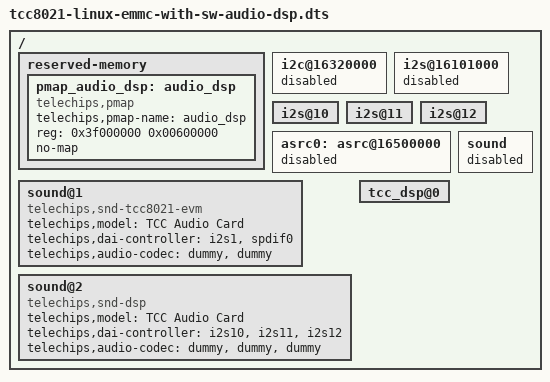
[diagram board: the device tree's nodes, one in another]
/*
 * Device tree for Telechips TCC8020 AVN board
 *
 * Copyright (C) 2016 Telechips Inc. - http://www.telechips.com
 *
 * This file is dual-licensed: you can use it either under the terms
 * of the GPL or the X11 license, at your option. Note that this dual
 * licensing only applies to this file, and not this project as a
 * whole.
 *
 *  a) This file is free software; you can redistribute it and/or
 *     modify it under the terms of the GNU General Public License as
 *     published by the Free Software Foundation; either version 2 of the
 *     License, or (at your option) any later version.
 *
 *     This file is distributed in the hope that it will be useful,
 *     but WITHOUT ANY WARRANTY; without even the implied warranty of
 *     MERCHANTABILITY or FITNESS FOR A PARTICULAR PURPOSE.  See the
 *     GNU General Public License for more details.
 *
 * Or, alternatively,
 *
 *  b) Permission is hereby granted, free of charge, to any person
 *     obtaining a copy of this software and associated documentation
 *     files (the "Software"), to deal in the Software without
 *     restriction, including without limitation the rights to use,
 *     copy, modify, merge, publish, distribute, sublicense, and/or
 *     sell copies of the Software, and to permit persons to whom the
 *     Software is furnished to do so, subject to the following
 *     conditions:
 *
 *     The above copyright notice and this permission notice shall be
 *     included in all copies or substantial portions of the Software.
 *
 *     THE SOFTWARE IS PROVIDED "AS IS", WITHOUT WARRANTY OF ANY KIND,
 *     EXPRESS OR IMPLIED, INCLUDING BUT NOT LIMITED TO THE WARRANTIES
 *     OF MERCHANTABILITY, FITNESS FOR A PARTICULAR PURPOSE AND
 *     NONINFRINGEMENT. IN NO EVENT SHALL THE AUTHORS OR COPYRIGHT
 *     HOLDERS BE LIABLE FOR ANY CLAIM, DAMAGES OR OTHER LIABILITY,
 *     WHETHER IN AN ACTION OF CONTRACT, TORT OR OTHERWISE, ARISING
 *     FROM, OUT OF OR IN CONNECTION WITH THE SOFTWARE OR THE USE OR
 *     OTHER DEALINGS IN THE SOFTWARE.
 */

#include "tcc8021-linux-emmc-fld0800-micom.dts"

/ {
	reserved-memory {
		pmap_audio_dsp: audio_dsp{
			compatible = "telechips,pmap";
			telechips,pmap-name = "audio_dsp";
			reg = <0x3f000000 0x00600000>;
			no-map;
		};
	};

	i2c@16320000 {
		status = "disabled";
	};

	i2s@16101000 {
		status = "disabled";
	};

	i2s@10 {
		status = "okay";
	};

	i2s@11 {
		status = "okay";
	};

	i2s@12 {
		status = "okay";
	};

	asrc0: asrc@16500000 {
		status = "disabled";
	};

	sound {
		status = "disabled";
	};

	sound@1 {
		compatible = "telechips,snd-tcc8021-evm";
		telechips,model = "TCC Audio Card";

		telechips,dai-controller = <&i2s1 &spdif0>;
		telechips,audio-codec = <&dummy &dummy>;
		status="okay";
	};

	sound@2 {
		compatible = "telechips,snd-dsp";
		telechips,model = "TCC Audio Card";

		telechips,dai-controller = <&i2s10 &i2s11 &i2s12>;
		telechips,audio-codec = <&dummy &dummy &dummy>;
		status="okay";
	};

	tcc_dsp@0 {
		status="okay";
	};
};
